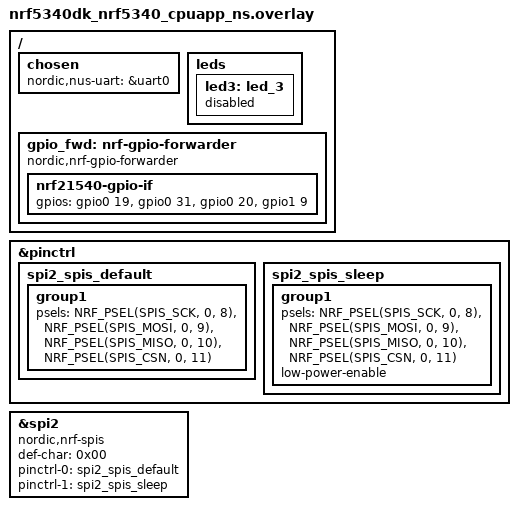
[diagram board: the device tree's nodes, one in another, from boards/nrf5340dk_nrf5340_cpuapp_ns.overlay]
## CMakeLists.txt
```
#
# Copyright (c) 2018 Nordic Semiconductor
#
# SPDX-License-Identifier: LicenseRef-Nordic-5-Clause
#
cmake_minimum_required(VERSION 3.20.0)

find_package(Zephyr REQUIRED HINTS $ENV{ZEPHYR_BASE})
project(peripheral_uart)

# NORDIC SDK APP START
target_sources(app PRIVATE
  src/main.c
  src/spi_slave.c
  src/ble_comm.c
)

# Tell Zephyr where to find spi_ble_queue.h
target_include_directories(app PRIVATE
  ${CMAKE_CURRENT_SOURCE_DIR}/inc
)

# NORDIC SDK APP END
```

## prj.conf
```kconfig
#
# Copyright (c) 2018 Nordic Semiconductor
#
# SPDX-License-Identifier: LicenseRef-Nordic-5-Clause
#

# Enable the UART driver
CONFIG_UART_ASYNC_API=y
CONFIG_NRFX_UARTE0=y
CONFIG_SERIAL=y

CONFIG_GPIO=y

# Make sure printk is printing to the UART console
CONFIG_CONSOLE=y
CONFIG_UART_CONSOLE=n


# CONFIG_DK_LIBRARY=y
CONFIG_DK_LIBRARY=n

# Give main and system workqueue more headroom
CONFIG_MAIN_STACK_SIZE=4096
CONFIG_SYSTEM_WORKQUEUE_STACK_SIZE=4096

# Make BT RX thread a bit fatter too
CONFIG_BT_RX_STACK_SIZE=2048

CONFIG_HEAP_MEM_POOL_SIZE=2048

CONFIG_BT=y
CONFIG_BT_PERIPHERAL=y
CONFIG_BT_DEVICE_NAME="DroneBLE"
CONFIG_BT_MAX_CONN=1
CONFIG_BT_MAX_PAIRED=1

# Enable the NUS service
CONFIG_BT_NUS=y

# Enable bonding
CONFIG_BT_SETTINGS=y
CONFIG_FLASH=y
CONFIG_FLASH_PAGE_LAYOUT=y
CONFIG_FLASH_MAP=y

# Enable DK LED and Buttons library
CONFIG_DK_LIBRARY=y

CONFIG_SYSTEM_WORKQUEUE_STACK_SIZE=2048
# Config logger
CONFIG_LOG=y
CONFIG_LOG_DEFAULT_LEVEL=3
CONFIG_USE_SEGGER_RTT=y
CONFIG_LOG_BACKEND_RTT=y
CONFIG_LOG_BACKEND_UART=n
CONFIG_LOG_PRINTK=y
CONFIG_RTT_CONSOLE=y


CONFIG_ASSERT=y

# SPI / SPIS support
CONFIG_SPI=y
CONFIG_SPI_SLAVE=y        # be explicit that we use slave mode

# Nordic SPIS2 (since we use &spi2)
CONFIG_NRFX_SPIS2=y


# ---- BLE MTU / buffers (host side, app core) ----
# Max L2CAP MTU we support
CONFIG_BT_L2CAP_TX_MTU=247

# ACL buffer sizes on host side (match controller side)
CONFIG_BT_BUF_ACL_TX_SIZE=251
CONFIG_BT_BUF_ACL_RX_SIZE=251
CONFIG_BT_BUF_ACL_TX_COUNT=10
CONFIG_BT_BUF_ACL_RX_COUNT=10

CONFIG_BT_GATT_CLIENT=y
```

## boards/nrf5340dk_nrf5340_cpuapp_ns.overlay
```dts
/ {
    chosen {
        nordic,nus-uart = &uart0;  /* keeps DT happy; code won't use it */
    };

    /* Disable LED3, since we use P0.31 for FEM RX_EN */
    leds {
        led3: led_3 {
            status = "disabled";
        };
    };

    /* Forward FEM GPIOs from app core to net core */
    gpio_fwd: nrf-gpio-forwarder {
        compatible = "nordic,nrf-gpio-forwarder";
        status = "okay";

        /* Remove any 'uart { ... }' child here – we don't want 0.10/0.11 forwarded */
        nrf21540-gpio-if {
            gpios = <&gpio0 19 0>,   /* TX_EN */
                    <&gpio0 31 0>,   /* RX_EN */
                    <&gpio0 20 0>,   /* PDN  */
                    <&gpio1  9 0>;   /* MODE */
        };
    };
};

&pinctrl {
    spi2_spis_default: spi2_spis_default {
        group1 {
            /* SPIS on: SCK=P0.08, MOSI=P0.09, MISO=P0.10, CSN=P0.11 */
            psels = <NRF_PSEL(SPIS_SCK,  0, 8)>,
                    <NRF_PSEL(SPIS_MOSI, 0, 9)>,
                    <NRF_PSEL(SPIS_MISO, 0, 10)>,
                    <NRF_PSEL(SPIS_CSN,  0, 11)>;
        };
    };

    spi2_spis_sleep: spi2_spis_sleep {
        group1 {
            psels = <NRF_PSEL(SPIS_SCK,  0, 8)>,
                    <NRF_PSEL(SPIS_MOSI, 0, 9)>,
                    <NRF_PSEL(SPIS_MISO, 0, 10)>,
                    <NRF_PSEL(SPIS_CSN,  0, 11)>;
            low-power-enable;
        };
    };
};

&spi2 {
    compatible = "nordic,nrf-spis";
    status = "okay";

    def-char = <0x00>;

    pinctrl-0 = <&spi2_spis_default>;
    pinctrl-1 = <&spi2_spis_sleep>;
    pinctrl-names = "default", "sleep";
};

&gpio_fwd {
    /delete-node/ uart;

    /* keep status + FEM pins as you want them */
    status = "okay";

    nrf21540-gpio-if {
        gpios = < &gpio0 19 0 >,    /* TX_EN */
                < &gpio0 31 0 >,    /* RX_EN */
                < &gpio0 20 0 >,    /* PDN  */
                < &gpio1  9 0 >;    /* MODE */
    };
};
```

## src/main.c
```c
/*
 * Copyright (c) 2018 Nordic Semiconductor ASA
 *
 * SPDX-License-Identifier: LicenseRef-Nordic-5-Clause
 */

/** @file
 *  @brief Nordic UART Bridge Service (NUS) sample
 */

#include "ble_comm.h"

void spi_slave_init(void);

int main(void)
{
	int blink_status = 0;
	int err = ble_comm_init();

    if (err) {
        printk("BLE init failed (err %d)\n", err);
        return err;
    }

	for (;;) {
		dk_set_led(RUN_STATUS_LED, (++blink_status) % 2);
		k_sleep(K_MSEC(RUN_LED_BLINK_INTERVAL));
	}
}
```

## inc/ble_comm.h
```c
#ifndef BLE_COMM_H_
#define BLE_COMM_H_
#include <uart_async_adapter.h>

#include <zephyr/types.h>
#include <zephyr/kernel.h>
#include <zephyr/drivers/uart.h>
#include <zephyr/usb/usb_device.h>

#include <zephyr/device.h>
#include <zephyr/devicetree.h>
#include <soc.h>

#include <zephyr/bluetooth/bluetooth.h>
#include <zephyr/bluetooth/uuid.h>
#include <zephyr/bluetooth/gatt.h>
#include <zephyr/bluetooth/hci.h>

#include <bluetooth/services/nus.h>

#include <dk_buttons_and_leds.h>

#include <zephyr/settings/settings.h>

#include <stdio.h>
#include <string.h>

#include <zephyr/logging/log.h>

#include <zephyr/drivers/gpio.h>

#include "spi_ble_queue.h"

#define STACKSIZE CONFIG_BT_NUS_THREAD_STACK_SIZE
#define PRIORITY 7

#define DEVICE_NAME CONFIG_BT_DEVICE_NAME
#define DEVICE_NAME_LEN	(sizeof(DEVICE_NAME) - 1)

#define RUN_STATUS_LED DK_LED1
#define RUN_LED_BLINK_INTERVAL 1000

#define CON_STATUS_LED DK_LED2

#define KEY_PASSKEY_ACCEPT DK_BTN1_MSK
#define KEY_PASSKEY_REJECT DK_BTN2_MSK

#define UART_BUF_SIZE CONFIG_BT_NUS_UART_BUFFER_SIZE
#define UART_WAIT_FOR_BUF_DELAY K_MSEC(50)
#define UART_WAIT_FOR_RX CONFIG_BT_NUS_UART_RX_WAIT_TIME


#include <zephyr/device.h>
#include <zephyr/drivers/gpio.h>
#include <zephyr/kernel.h>
#include <zephyr/device.h>
#include <zephyr/drivers/gpio.h>
#include <zephyr/kernel.h>
#include <zephyr/bluetooth/gatt.h>

#define FEM_PDN_PIN   20   /* P0.20 */
#define FEM_TXEN_PIN  19   /* P0.19 */
#define FEM_RXEN_PIN  31   /* P0.31 */
#define FEM_MODE_PIN  9    /* P1.09 */

/* Initialize BLE stack + NUS service and start advertising */
int ble_comm_init(void);

/* Return true if there is an active BLE connection */
bool ble_comm_is_connected(void);

/* Send data over NUS. Splitting into chunks if needed, if you want. */
int ble_comm_send(const uint8_t *data, size_t len);

bool get_nus_ble_data_available();

uint8_t * get_nus_ble_data();

void reset_nus_ble_data_available();

int get_nus_ble_data_len();

#endif /* BLE_COMM_H_ */
```

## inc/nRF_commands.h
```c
#ifndef NRF_COMMANDS_H_
#define NRF_COMMANDS_H_

/* nRF Commands Specs.
 * There are two kinds of commands: One-Shot commands and multi-shot.
 *
 * One-shot commands: 	these are commands that will execute a particular task on the nRF just after the command
 * 						is received.
 * Multi-shot commands: these commands will always start with a One-shot command that will inform the nRF that
 * 						we will send more data. After sending the first one shot command, the nRF will expect
 * 						to receive the size of the data to be transmitted in the next transmission. Finally,
 * 						after these two first bytes of commands, you can start putting your payload.
 *
 * 						ex:
 *
 * 						send_spi(_SEND_OVER_Bt);
 * 						send_spi(SIZE_DATA);
 * 						send_spi(ALL_THE_PAYLOAD_VECTOR)
 * */

/*One shot commands - - - - - - - - - - - - - - - - - - - - - - - - -*/

/* General Commands to control stuff using the nordic*/
#define _ENABLE_ANALOG					0x55
#define _DISABLE_ANALOG					0x50
#define _LEAVING_MASTER_MODE            0XF0

#define _SET_BLE_BUFFER_NORDIC          0x36
#define _RETRIEVE_BLE_PCK_SIZE          0X37
#define _RETRIEVE_BLE_PCK               0x38
#define _SEND_OVER_NUS                  0x69

#define _ENQ_BATTERY_VOLTAGE_VALUE    	0x14
#define _ENQ_8_RC_CHANNELS              0x15

/* Led functions */
#define _LED_1_ON                       0x21
#define _LED_1_OFF                      0x22
#define _LED_2_ON                       0x25
#define _LED_2_OFF                      0x26

/*Multi-shot commands - - - - - - - - - - - - - - - - - - - - - - - - -*/
#define	_SEND_OVR_BT_SINGLE				0x66
#define _ENABLE_BLE						0x35

#define BLE_UART_MSG                    0x40
#define BLE_NO_MSG                      0x41

/*SPI PACKET IDENT DEFINES*/
/*SPI packets will be defined*/













#endif
```

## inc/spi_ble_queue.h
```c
#ifndef _SPI_BLE_QUEUE_H_
#define _SPI_BLE_QUEUE_H_

#include <zephyr/kernel.h>


#define SPI_PACKET_MAX_LEN  256      // or whatever max you expect (ret-2)
#define SPI_PACKET_QUEUE_LEN 8       // number of packets buffered

struct spi_packet {
    uint16_t len;
    uint8_t  data[SPI_PACKET_MAX_LEN];
};

#endif
```

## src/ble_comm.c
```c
#include "ble_comm.h"
#include "spi_ble_queue.h"

LOG_MODULE_REGISTER(ble_comm, LOG_LEVEL_INF);

static K_SEM_DEFINE(ble_init_ok, 0, 1);

static struct bt_conn *current_conn;
static struct bt_conn *auth_conn;
static struct k_work adv_work;

static const struct device *uart = DEVICE_DT_GET(DT_CHOSEN(nordic_nus_uart));
static struct k_work_delayable uart_work;

struct uart_data_t {
	void *fifo_reserved;
	uint8_t data[UART_BUF_SIZE];
	uint16_t len;
};

struct k_msgq spi_packet_msgq;


K_MSGQ_DEFINE(spi_packet_msgq,
              sizeof(struct spi_packet),
              SPI_PACKET_QUEUE_LEN,
              4); // alignment

static K_FIFO_DEFINE(fifo_uart_tx_data);
static K_FIFO_DEFINE(fifo_uart_rx_data);

static const struct bt_data ad[] = {
	BT_DATA_BYTES(BT_DATA_FLAGS, (BT_LE_AD_GENERAL | BT_LE_AD_NO_BREDR)),
	BT_DATA(BT_DATA_NAME_COMPLETE, DEVICE_NAME, DEVICE_NAME_LEN),
};

static const struct bt_data sd[] = {
	BT_DATA_BYTES(BT_DATA_UUID128_ALL, BT_UUID_NUS_VAL),
};

#ifdef CONFIG_UART_ASYNC_ADAPTER
UART_ASYNC_ADAPTER_INST_DEFINE(async_adapter);
#else
#define async_adapter NULL
#endif

#define BLE_HANDSHAKE_IN_NODE   DT_NODELABEL(gpio0)
#define BLE_HANDSHAKE_OUT_NODE  DT_NODELABEL(gpio1)

#define BLE_HANDSHAKE_IN_PIN    12   /* P0.12 */
#define BLE_HANDSHAKE_OUT_PIN   0    /* P1.00 */

static const struct device * const gpio0_dev = DEVICE_DT_GET(BLE_HANDSHAKE_IN_NODE);
static const struct device * const gpio1_dev = DEVICE_DT_GET(BLE_HANDSHAKE_OUT_NODE);

static bool ble_connected = false;

bool ble_comm_is_connected(void)
{
    return ble_connected;
}


static int ble_handshake_gpio_init(void)
{
    int ret;

    if (!device_is_ready(gpio0_dev)) {
        printk("gpio0 device not ready\n");
        return -ENODEV;
    }

    if (!device_is_ready(gpio1_dev)) {
        printk("gpio1 device not ready\n");
        return -ENODEV;
    }

    /* P0.12 as input (you can change pull if needed) */
    ret = gpio_pin_configure(gpio0_dev,
                             BLE_HANDSHAKE_IN_PIN,
                             GPIO_INPUT | GPIO_PULL_DOWN);
    if (ret) {
        printk("Failed to config P0.12 as input: %d\n", ret);
        return ret;
    }

    /* P1.00 as output, default low, active-high */
    ret = gpio_pin_configure(gpio1_dev,
                             BLE_HANDSHAKE_OUT_PIN,
                             GPIO_OUTPUT_INACTIVE | GPIO_ACTIVE_HIGH);
    if (ret) {
        printk("Failed to config P1.00 as output: %d\n", ret);
        return ret;
    }

    return 0;
}

void ble_handshake_set(bool level)
{
    /* level = true → set P1.00 high (slave has data)
     * level = false → set P1.00 low
     */
    gpio_pin_set(gpio1_dev, BLE_HANDSHAKE_OUT_PIN, level ? 1 : 0);
}

int ble_handshake_read(void)
{
    /* Read P0.12 (master signal) */
    return gpio_pin_get(gpio0_dev, BLE_HANDSHAKE_IN_PIN);
}


void ble_handshake_toggle()
{
    /* level = true → set P1.00 high (slave has data)
     * level = false → set P1.00 low
     */
    int ret = gpio_pin_toggle(gpio1_dev, BLE_HANDSHAKE_OUT_PIN);

	if (ret) {
        printk("Failed to toggle P1.00: %d\n", ret);
    }
}


static size_t ble_get_max_payload(void)
{
    /* Default ATT MTU is 23 bytes (20 bytes payload) */
    uint16_t att_mtu = 23U;

    struct bt_conn *conn = current_conn;

    if (conn != NULL) {
        uint16_t tmp = bt_gatt_get_mtu(conn);

        /* bt_gatt_get_mtu() should be >= 23 when connected, but be safe */
        if (tmp >= 23U) {
            att_mtu = tmp;
        }
    }

    /* ATT header is 3 bytes → payload = MTU - 3 */
    uint16_t max_payload = (att_mtu > 3U) ? (att_mtu - 3U) : 20U;

    /* Do not exceed what fits in one SPI packet */
    if (max_payload > SPI_PACKET_MAX_LEN) {
        max_payload = SPI_PACKET_MAX_LEN;
    }

    return (size_t)max_payload;
}




static struct bt_gatt_exchange_params mtu_exchange_params;

static void mtu_exchange_cb(struct bt_conn *conn, uint8_t err,
                            struct bt_gatt_exchange_params *params)
{
    if (!err) {
        uint16_t mtu = bt_gatt_get_mtu(conn);
        printk("MTU exchange done, new MTU = %d\n", mtu);
    } else {
        printk("MTU exchange failed (err %u)\n", err);
    }
}

void ble_send(uint8_t *data, int size)
{
    if (!ble_connected) {
        return;
    }

    struct bt_conn *conn = current_conn; // however you're storing it
    uint16_t att_mtu = bt_gatt_get_mtu(conn);
    uint16_t max_payload = att_mtu - 3;  // safe payload per notification
	//printk("max_payload = %d\r\n", max_payload);

    int offset = 0;
    while (offset < size) {
        int chunk = size - offset;
        if (chunk > max_payload) {
            chunk = max_payload;
        }

        int err = bt_nus_send(conn, &data[offset], chunk);
        if (err) {
            printk("bt_nus_send failed (err %d)\n", err);
            break;
        }

        offset += chunk;
    }
}

static void adv_work_handler(struct k_work *work)
{
	int err = bt_le_adv_start(BT_LE_ADV_CONN_FAST_2, ad, ARRAY_SIZE(ad), sd, ARRAY_SIZE(sd));

	if (err) {
		LOG_ERR("Advertising failed to start (err %d)", err);
		return;
	}

	LOG_INF("Advertising successfully started");
}

static void advertising_start(void)
{
	k_work_submit(&adv_work);
}

static void connected(struct bt_conn *conn, uint8_t err)
{
	char addr[BT_ADDR_LE_STR_LEN];

	if (err) {
		LOG_ERR("Connection failed, err 0x%02x %s", err, bt_hci_err_to_str(err));
		return;
	}

	bt_addr_le_to_str(bt_conn_get_dst(conn), addr, sizeof(addr));
	LOG_INF("Connected %s", addr);
	
	ble_connected = true;

	current_conn = bt_conn_ref(conn);

	dk_set_led_on(CON_STATUS_LED);


	/*  Example: request 30–50 ms connection interval, no latency, 4 s timeout
     *  min_interval = 24 * 1.25 ms = 30 ms
     *  max_interval = 40 * 1.25 ms = 50 ms
     *  timeout      = 400 * 10 ms = 4 s
     */
    struct bt_le_conn_param param = {
        .interval_min = 12,
        .interval_max = 24,
        .latency      = 0,
        .timeout      = 500,
    };

    int rc = bt_conn_le_param_update(conn, &param);
    if (rc) {
        printk("conn param update failed (err %d)\n", rc);
    }

	mtu_exchange_params.func = mtu_exchange_cb;

    int ret = bt_gatt_exchange_mtu(conn, &mtu_exchange_params);
    
	if (ret) {
        printk("bt_gatt_exchange_mtu failed (err %d)\n", ret);
    }
}

static void disconnected(struct bt_conn *conn, uint8_t reason)
{
	
	ble_connected = false;

	char addr[BT_ADDR_LE_STR_LEN];

	bt_addr_le_to_str(bt_conn_get_dst(conn), addr, sizeof(addr));

	LOG_INF("Disconnected: %s, reason 0x%02x %s", addr, reason, bt_hci_err_to_str(reason));

	if (auth_conn) {
		bt_conn_unref(auth_conn);
		auth_conn = NULL;
	}

	if (current_conn) {
		bt_conn_unref(current_conn);
		current_conn = NULL;
		dk_set_led_off(CON_STATUS_LED);
	}
}

static void recycled_cb(void)
{
	LOG_INF("Connection object available from previous conn. Disconnect is complete!");
	advertising_start();
}

#ifdef CONFIG_BT_NUS_SECURITY_ENABLED
static void security_changed(struct bt_conn *conn, bt_security_t level,
			     enum bt_security_err err)
{
	char addr[BT_ADDR_LE_STR_LEN];

	bt_addr_le_to_str(bt_conn_get_dst(conn), addr, sizeof(addr));

	if (!err) {
		LOG_INF("Security changed: %s level %u", addr, level);
	} else {
		LOG_WRN("Security failed: %s level %u err %d %s", addr, level, err,
			bt_security_err_to_str(err));
	}
}
#endif

BT_CONN_CB_DEFINE(conn_callbacks) = {
	.connected        = connected,
	.disconnected     = disconnected,
	.recycled         = recycled_cb,
#ifdef CONFIG_BT_NUS_SECURITY_ENABLED
	.security_changed = security_changed,
#endif
};

#if defined(CONFIG_BT_NUS_SECURITY_ENABLED)
static void auth_passkey_display(struct bt_conn *conn, unsigned int passkey)
{
	char addr[BT_ADDR_LE_STR_LEN];

	bt_addr_le_to_str(bt_conn_get_dst(conn), addr, sizeof(addr));

	LOG_INF("Passkey for %s: %06u", addr, passkey);
}

static void auth_passkey_confirm(struct bt_conn *conn, unsigned int passkey)
{
	char addr[BT_ADDR_LE_STR_LEN];

	auth_conn = bt_conn_ref(conn);

	bt_addr_le_to_str(bt_conn_get_dst(conn), addr, sizeof(addr));

	LOG_INF("Passkey for %s: %06u", addr, passkey);

	if (IS_ENABLED(CONFIG_SOC_SERIES_NRF54HX) || IS_ENABLED(CONFIG_SOC_SERIES_NRF54LX)) {
		LOG_INF("Press Button 0 to confirm, Button 1 to reject.");
	} else {
		LOG_INF("Press Button 1 to confirm, Button 2 to reject.");
	}
}


static void auth_cancel(struct bt_conn *conn)
{
	char addr[BT_ADDR_LE_STR_LEN];

	bt_addr_le_to_str(bt_conn_get_dst(conn), addr, sizeof(addr));

	LOG_INF("Pairing cancelled: %s", addr);
}


static void pairing_complete(struct bt_conn *conn, bool bonded)
{
	char addr[BT_ADDR_LE_STR_LEN];

	bt_addr_le_to_str(bt_conn_get_dst(conn), addr, sizeof(addr));

	LOG_INF("Pairing completed: %s, bonded: %d", addr, bonded);
}


static void pairing_failed(struct bt_conn *conn, enum bt_security_err reason)
{
	char addr[BT_ADDR_LE_STR_LEN];

	bt_addr_le_to_str(bt_conn_get_dst(conn), addr, sizeof(addr));

	LOG_INF("Pairing failed conn: %s, reason %d %s", addr, reason,
		bt_security_err_to_str(reason));
}

static struct bt_conn_auth_cb conn_auth_callbacks = {
	.passkey_display = auth_passkey_display,
	.passkey_confirm = auth_passkey_confirm,
	.cancel = auth_cancel,
};

static struct bt_conn_auth_info_cb conn_auth_info_callbacks = {
	.pairing_complete = pairing_complete,
	.pairing_failed = pairing_failed
};
#else
static struct bt_conn_auth_cb conn_auth_callbacks;
static struct bt_conn_auth_info_cb conn_auth_info_callbacks;
#endif

uint8_t nus_ble_data[255];
int nus_ble_data_len = 0;
bool nus_ble_data_available = false;

bool get_nus_ble_data_available()
{
	if(nus_ble_data_available)
		return true;

	return false;
}

void reset_nus_ble_data_available()
{
	nus_ble_data_available = false;
}

int get_nus_ble_data_len()
{
	return nus_ble_data_len;
}

uint8_t * get_nus_ble_data()
{
	return nus_ble_data;
}

static void bt_receive_cb(struct bt_conn *conn, const uint8_t *const data,
			  uint16_t len)
{
	int err;
	char addr[BT_ADDR_LE_STR_LEN] = {0};

	bt_addr_le_to_str(bt_conn_get_dst(conn), addr, ARRAY_SIZE(addr));

	LOG_INF("Received data from: %s", addr);

	ble_handshake_toggle();

	memcpy(nus_ble_data, data, len);

	nus_ble_data_len = len;

	nus_ble_data_available = true;

	// for (uint16_t pos = 0; pos != len;) {
	// 	struct uart_data_t *tx = k_malloc(sizeof(*tx));

	// 	if (!tx) {
	// 		LOG_WRN("Not able to allocate UART send data buffer");
	// 		return;
	// 	}

	// 	/* Keep the last byte of TX buffer for potential LF char. */
	// 	size_t tx_data_size = sizeof(tx->data) - 1;

	// 	if ((len - pos) > tx_data_size) {
	// 		tx->len = tx_data_size;
	// 	} else {
	// 		tx->len = (len - pos);
	// 	}

	// 	memcpy(tx->data, &data[pos], tx->len);

	// 	pos += tx->len;

	// 	/* Append the LF character when the CR character triggered
	// 	 * transmission from the peer.
	// 	 */
	// 	if ((pos == len) && (data[len - 1] == '\r')) {
	// 		tx->data[tx->len] = '\n';
	// 		tx->len++;
	// 	}

	// 	err = uart_tx(uart, tx->data, tx->len, SYS_FOREVER_MS);
	// 	if (err) {
	// 		k_fifo_put(&fifo_uart_tx_data, tx);
	// 	}
	// }
}

static struct bt_nus_cb nus_cb = {
	.received = bt_receive_cb,
};

void error(void)
{
	dk_set_leds_state(DK_ALL_LEDS_MSK, DK_NO_LEDS_MSK);

	while (true) {
		/* Spin for ever */
		k_sleep(K_MSEC(1000));
	}
}

#ifdef CONFIG_BT_NUS_SECURITY_ENABLED
static void num_comp_reply(bool accept)
{
	if (accept) {
		bt_conn_auth_passkey_confirm(auth_conn);
		LOG_INF("Numeric Match, conn %p", (void *)auth_conn);
	} else {
		bt_conn_auth_cancel(auth_conn);
		LOG_INF("Numeric Reject, conn %p", (void *)auth_conn);
	}

	bt_conn_unref(auth_conn);
	auth_conn = NULL;
}

void button_changed(uint32_t button_state, uint32_t has_changed)
{
	uint32_t buttons = button_state & has_changed;

	if (auth_conn) {
		if (buttons & KEY_PASSKEY_ACCEPT) {
			num_comp_reply(true);
		}

		if (buttons & KEY_PASSKEY_REJECT) {
			num_comp_reply(false);
		}
	}
}
#endif /* CONFIG_BT_NUS_SECURITY_ENABLED */


int ble_comm_init(void)
{
	int err = 0;

	err = ble_handshake_gpio_init();

    if (err) {
        printk("Handshake GPIO init failed: %d\n", err);
        return err;
    }

	if (IS_ENABLED(CONFIG_BT_NUS_SECURITY_ENABLED)) {
		err = bt_conn_auth_cb_register(&conn_auth_callbacks);
		if (err) {
			LOG_ERR("Failed to register authorization callbacks. (err: %d)", err);
			return 0;
		}

		err = bt_conn_auth_info_cb_register(&conn_auth_info_callbacks);
		if (err) {
			LOG_ERR("Failed to register authorization info callbacks. (err: %d)", err);
			return 0;
		}
	}

	err = bt_enable(NULL);
	if (err) {
		error();
	}

	LOG_INF("Bluetooth initialized");

    
	k_sem_give(&ble_init_ok);

	if (IS_ENABLED(CONFIG_SETTINGS)) {
		settings_load();
	}

	err = bt_nus_init(&nus_cb);
	if (err) {
		LOG_ERR("Failed to initialize UART service (err: %d)", err);
		return 0;
	}

	k_work_init(&adv_work, adv_work_handler);
	advertising_start();

}


void ble_write_thread(void)
{
    struct spi_packet pkt;
    static uint8_t agg_buf[SPI_PACKET_MAX_LEN];
    size_t agg_len = 0U;

    while (1) {
        /* Drop any partial buffer if the link went down */
        if (!ble_connected && agg_len > 0U) {
            agg_len = 0U;
        }

        /* If we already have data, wait up to 10 ms for more.
         * Otherwise, block until the first packet arrives.
         */
        k_timeout_t timeout = (agg_len == 0U) ? K_FOREVER : K_MSEC(10);

        int ret = k_msgq_get(&spi_packet_msgq, &pkt, timeout);

        if (ret == 0) {
            /* New SPI packet available */
            if (!ble_connected) {
                /* Not connected: drop packet and any partial buffer */
                agg_len = 0U;
                continue;
            }

            size_t max_payload = ble_get_max_payload();
            size_t offset = 0U;

            while (offset < pkt.len) {
                size_t space    = max_payload - agg_len;
                size_t copy_len = pkt.len - offset;

                if (space == 0U) {
                    /* Active buffer full, push it out and start again */
                    ble_send(agg_buf, agg_len);
                    agg_len = 0U;

                    max_payload = ble_get_max_payload();
                    space       = max_payload;
                }

                if (copy_len > space) {
                    copy_len = space;
                }

                memcpy(&agg_buf[agg_len], &pkt.data[offset], copy_len);
                agg_len += copy_len;
                offset  += copy_len;

                if (agg_len == max_payload) {
                    /* We reached exactly one MTU payload: send immediately */
                    ble_send(agg_buf, agg_len);
                    agg_len = 0U;

                    max_payload = ble_get_max_payload();
                }
            }
        } else {
            /* Timeout (no new SPI data within 10 ms) or other error:
             * flush any pending data in the active buffer.
             */
            if (agg_len > 0U && ble_connected) {
                ble_send(agg_buf, agg_len);
                agg_len = 0U;
            }
        }
    }
}

K_THREAD_DEFINE(ble_write_thread_id, STACKSIZE, ble_write_thread, NULL, NULL,
		NULL, PRIORITY, 0, 0);
```

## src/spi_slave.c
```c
#include <zephyr/kernel.h>
#include <zephyr/device.h>
#include <zephyr/devicetree.h>
#include <zephyr/drivers/spi.h>
#include <zephyr/sys/printk.h>
#include <bluetooth/services/nus.h>
#include "spi_ble_queue.h"
#include "nRF_commands.h"
#include "ble_comm.h"


#define LOG_LEVEL LOG_LEVEL_DBG
#include <zephyr/logging/log.h>
LOG_MODULE_REGISTER(spi_slave);

#define SPI_SLAVE_STACK_SIZE 2048 
#define SPI_SLAVE_PRIORITY   5
#define SPI_RX_BUF_SIZE      200
#define MIN_PCK_SIZE         2 // header and size.

#define SPI_TX_BUF_SIZE 200

static uint8_t spi_tx_buf[SPI_TX_BUF_SIZE];
static size_t  spi_tx_len = 0;


#define SPI_SLAVE_NODE DT_NODELABEL(spi2)
static const struct device *const spi_dev = DEVICE_DT_GET(SPI_SLAVE_NODE);

static K_THREAD_STACK_DEFINE(spi_slave_stack, SPI_SLAVE_STACK_SIZE);
static struct k_thread spi_slave_thread_data;

static uint8_t spi_rx_buf[SPI_RX_BUF_SIZE];

static const struct spi_config spi_cfg = {
    .operation = SPI_OP_MODE_SLAVE |
                 SPI_MODE_CPOL |
                 SPI_MODE_CPHA |        /* CPOL_LOW, CPHA_HIGH (mode 1) */
                 SPI_WORD_SET(8) |
                 SPI_TRANSFER_MSB,
    .frequency = 0,
    .slave = 0,
};

void ble_send(uint8_t *data, int size);

int counter = 0;
int16_t tx_size = 0;

extern struct k_msgq spi_packet_msgq;

uint8_t msg[] = "This is the BLE msg";

void set_ble_pck_size()
{
    // Example: payload coming from master in this command
    // is what you want to send back on the next transaction.
    // Adjust to your real protocol.


    spi_tx_buf[0] = 0x55;

    if(get_nus_ble_data_available())
    {
        spi_tx_buf[1] = BLE_UART_MSG;
        spi_tx_buf[2] = (uint8_t) get_nus_ble_data_len();
    }
    else
    {
        spi_tx_buf[1] = BLE_NO_MSG;
        spi_tx_buf[2] = 0;
    }

    LOG_INF("spi_tx_buf[2] = %d, and size = %d", spi_tx_buf[2], sizeof(msg));

    spi_tx_len = 3;

    // Prepare TX buffers
    struct spi_buf tx_buf = {
        .buf = spi_tx_buf,
        .len = spi_tx_len,
    };
    struct spi_buf_set tx = {
        .buffers = &tx_buf,
        .count   = 1,
    };

    // No RX here, master just reads
    int tret = spi_transceive(spi_dev, &spi_cfg, &tx, NULL);
    if (tret < 0) {
        LOG_ERR("spi_transceive (TX to master) failed: %d", tret);
    } else {
        LOG_DBG("Sent %d frames to master", tret);
    }
}

void set_ble_pck_data()
{
    // Example: payload coming from master in this command
    // is what you want to send back on the next transaction.
    // Adjust to your real protocol.

    spi_tx_buf[0] = 0x55;
    spi_tx_buf[1] = _RETRIEVE_BLE_PCK;

    uint8_t *nus_data = get_nus_ble_data();
    int ble_data_len = get_nus_ble_data_len();

    for(int inx_data = 0; inx_data<ble_data_len; inx_data++)
    {
        spi_tx_buf[inx_data+2] = nus_data[inx_data];
    }

    spi_tx_buf[2+ble_data_len] = 0xAA;
    
    spi_tx_len = 3+ble_data_len;

    // Prepare TX buffers
    struct spi_buf tx_buf = {
        .buf = spi_tx_buf,
        .len = spi_tx_len,
    };
    struct spi_buf_set tx = {
        .buffers = &tx_buf,
        .count   = 1,
    };

    // No RX here, master just reads
    int tret = spi_transceive(spi_dev, &spi_cfg, &tx, NULL);
    if (tret < 0) {
        LOG_ERR("spi_transceive (TX to master) failed: %d", tret);
    } else {
        LOG_DBG("Sent %d frames to master", tret);
    }

    reset_nus_ble_data_available();
    
}



static void spi_slave_thread(void *p1, void *p2, void *p3)
{
    ARG_UNUSED(p1); ARG_UNUSED(p2); ARG_UNUSED(p3);

    if (!device_is_ready(spi_dev)) {
        LOG_INF("SPIS device not ready");
        return;
    }

    LOG_INF("SPI slave thread started");

    while (1) {
        struct spi_buf rx_buf = {
            .buf = spi_rx_buf,
            .len = sizeof(spi_rx_buf),
        };
        struct spi_buf_set rx = {
            .buffers = &rx_buf,
            .count = 1,
        };

        int ret = spi_read(spi_dev, &spi_cfg, &rx);
        
        if (ret <= 0) {
            // you may want to LOG_ERR or handle specific errors here
            LOG_ERR("ERROR receiving SPIS data");
            continue;
        }

        // First two bytes are header + packet size → payload starts at index 2

        int payload_len = ret - MIN_PCK_SIZE;

        if(payload_len >= 0)
        {
            LOG_INF("Master-Request: 0x%x", spi_rx_buf[0]);
            switch (spi_rx_buf[0])
            {               
            
                /* Set the buffers so it can be read by the master */
            case _SET_BLE_BUFFER_NORDIC:
                LOG_INF("SPIS: Setting PACKET size!");
                set_ble_pck_size();
                break;

            case _RETRIEVE_BLE_PCK:
                LOG_INF("SPIS: Sending PCK!");
                set_ble_pck_data();
                break;
                
            case _SEND_OVER_NUS:
                
                /* Send the data over NUS/BLE */
                if (payload_len <= 0) {
                    continue;
                }
                if (payload_len > SPI_PACKET_MAX_LEN) {
                    payload_len = SPI_PACKET_MAX_LEN;  // clamp, or drop if you prefer
                }

                struct spi_packet pkt;
                pkt.len = (uint16_t)payload_len;
                memcpy(pkt.data, &spi_rx_buf[2], pkt.len);

                int qret = k_msgq_put(&spi_packet_msgq, &pkt, K_NO_WAIT);
                if (qret != 0) {
                    // queue full → decide policy: drop oldest, drop new, or block
                    // simple approach: drop and optionally count/log
                    // LOG_WRN("SPI packet queue full, dropping packet");
                }
                break;
                
            default:
                /* Do nothing with packets that are unknown */
                break;
                
            }
        }

    }
}

/* Thread starts automatically at boot */
K_THREAD_DEFINE(spi_slave_thread_id,
                SPI_SLAVE_STACK_SIZE,
                spi_slave_thread,
                NULL, NULL, NULL,
                SPI_SLAVE_PRIORITY,
                0,
                0);
```
